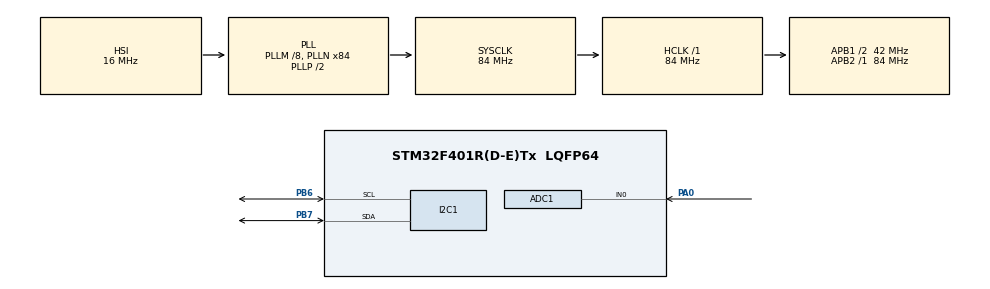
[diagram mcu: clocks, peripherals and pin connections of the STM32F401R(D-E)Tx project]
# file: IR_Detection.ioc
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ADC1.Channel-11\#ChannelRegularConversion=ADC_CHANNEL_0
<<<<<<< HEAD
ADC1.ClockPrescaler=ADC_CLOCK_SYNC_PCLK_DIV4
ADC1.ContinuousConvMode=DISABLE
ADC1.DMAContinuousRequests=ENABLE
ADC1.DataAlign=ADC_DATAALIGN_RIGHT
ADC1.DiscontinuousConvMode=ENABLE
ADC1.EOCSelection=ADC_EOC_SINGLE_CONV
ADC1.EnableAnalogWatchDog=false
ADC1.ExternalTrigConv=ADC_EXTERNALTRIGCONV_T2_TRGO
ADC1.ExternalTrigConvEdge=ADC_EXTERNALTRIGCONVEDGE_RISING
ADC1.InjNumberOfConversion=0
ADC1.NbrOfConversion=1
ADC1.NbrOfConversionFlag=1
ADC1.NbrOfDiscConversion=1
ADC1.Rank-11\#ChannelRegularConversion=1
ADC1.Resolution=ADC_RESOLUTION_12B
ADC1.SamplingTime-11\#ChannelRegularConversion=ADC_SAMPLETIME_480CYCLES
ADC1.ScanConvMode=DISABLE
ADC1.master=1
Dma.ADC1.0.Direction=DMA_PERIPH_TO_MEMORY
Dma.ADC1.0.FIFOMode=DMA_FIFOMODE_DISABLE
Dma.ADC1.0.Instance=DMA2_Stream0
Dma.ADC1.0.MemDataAlignment=DMA_MDATAALIGN_WORD
Dma.ADC1.0.MemInc=DMA_MINC_ENABLE
Dma.ADC1.0.Mode=DMA_CIRCULAR
Dma.ADC1.0.PeriphDataAlignment=DMA_PDATAALIGN_WORD
Dma.ADC1.0.PeriphInc=DMA_PINC_DISABLE
Dma.ADC1.0.Priority=DMA_PRIORITY_HIGH
Dma.Request0=ADC1
=======
ADC1.ContinuousConvMode=ENABLE
ADC1.EOCSelection=ADC_EOC_SEQ_CONV
ADC1.NbrOfConversionFlag=1
ADC1.Rank-11\#ChannelRegularConversion=1
ADC1.SamplingTime-11\#ChannelRegularConversion=ADC_SAMPLETIME_3CYCLES
ADC1.master=1
>>>>>>> 8014290a4e73a4bcc694909df24c79fa8737d68c
Mcu.Family=STM32F4
<<<<<<< HEAD
=======
>>>>>>> 8014290a4e73a4bcc694909df24c79fa8737d68c
Mcu.Name=STM32F401R(D-E)Tx
Mcu.Package=LQFP64
<<<<<<< HEAD
=======
>>>>>>> 8014290a4e73a4bcc694909df24c79fa8737d68c
<<<<<<< HEAD
NVIC.DMA2_Stream0_IRQn=true\:0\:0\:false\:false\:true\:false
=======
>>>>>>> 8014290a4e73a4bcc694909df24c79fa8737d68c
NVIC.PriorityGroup=NVIC_PRIORITYGROUP_4
PA0-WKUP.Signal=ADCx_IN0
PB6.Mode=I2C
PB6.Signal=I2C1_SCL
PB7.Mode=I2C
PB7.Signal=I2C1_SDA
ProjectManager.HeapSize=0x200
ProjectManager.StackSize=0x400
ProjectManager.TargetToolchain=Makefile
<<<<<<< HEAD
=======
>>>>>>> 8014290a4e73a4bcc694909df24c79fa8737d68c
RCC.48MHZClocksFreq_Value=42000000
RCC.AHBFreq_Value=84000000
RCC.APB1CLKDivider=RCC_HCLK_DIV2
RCC.APB1Freq_Value=42000000
RCC.APB1TimFreq_Value=84000000
RCC.APB2Freq_Value=84000000
RCC.APB2TimFreq_Value=84000000
RCC.CortexFreq_Value=84000000
RCC.HCLKFreq_Value=84000000
RCC.HSE_VALUE=25000000
RCC.HSI_VALUE=16000000
RCC.LSE_VALUE=32768
RCC.PLLM=8
RCC.PLLN=84
RCC.SYSCLKFreq_VALUE=84000000
RCC.SYSCLKSource=RCC_SYSCLKSOURCE_PLLCLK
RCC.VCOOutputFreq_Value=168000000
SH.ADCx_IN0.0=ADC1_IN0,IN0
<<<<<<< HEAD
TIM2.Channel-PWM\ Generation1\ No\ Output=TIM_CHANNEL_1
TIM2.OCFastMode_PWM-PWM\ Generation1\ No\ Output=TIM_OCFAST_DISABLE
TIM2.Period=20
TIM2.Prescaler=2
TIM2.TIM_MasterOutputTrigger=TIM_TRGO_OC1
TIM2.TIM_MasterSlaveMode=TIM_MASTERSLAVEMODE_ENABLE
VP_TIM2_VS_ClockSourceINT.Mode=Internal
VP_TIM2_VS_no_output1.Mode=PWM Generation1 No Output
=======
>>>>>>> 8014290a4e73a4bcc694909df24c79fa8737d68c
board=custom

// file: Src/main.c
/**
  ******************************************************************************
  * @file           : main.c
  * @brief          : Main program body
  ******************************************************************************
  ** This notice applies to any and all portions of this file
  * that are not between comment pairs USER CODE BEGIN and
  * USER CODE END. Other portions of this file, whether
  * inserted by the user or by software development tools
  * are owned by their respective copyright owners.
  *
  * COPYRIGHT(c) 2018 STMicroelectronics
  *
  * Redistribution and use in source and binary forms, with or without modification,
  * are permitted provided that the following conditions are met:
  *   1. Redistributions of source code must retain the above copyright notice,
  *      this list of conditions and the following disclaimer.
  *   2. Redistributions in binary form must reproduce the above copyright notice,
  *      this list of conditions and the following disclaimer in the documentation
  *      and/or other materials provided with the distribution.
  *   3. Neither the name of STMicroelectronics nor the names of its contributors
  *      may be used to endorse or promote products derived from this software
  *      without specific prior written permission.
  *
  * THIS SOFTWARE IS PROVIDED BY THE COPYRIGHT HOLDERS AND CONTRIBUTORS "AS IS"
  * AND ANY EXPRESS OR IMPLIED WARRANTIES, INCLUDING, BUT NOT LIMITED TO, THE
  * IMPLIED WARRANTIES OF MERCHANTABILITY AND FITNESS FOR A PARTICULAR PURPOSE ARE
  * DISCLAIMED. IN NO EVENT SHALL THE COPYRIGHT HOLDER OR CONTRIBUTORS BE LIABLE
  * FOR ANY DIRECT, INDIRECT, INCIDENTAL, SPECIAL, EXEMPLARY, OR CONSEQUENTIAL
  * DAMAGES (INCLUDING, BUT NOT LIMITED TO, PROCUREMENT OF SUBSTITUTE GOODS OR
  * SERVICES; LOSS OF USE, DATA, OR PROFITS; OR BUSINESS INTERRUPTION) HOWEVER
  * CAUSED AND ON ANY THEORY OF LIABILITY, WHETHER IN CONTRACT, STRICT LIABILITY,
  * OR TORT (INCLUDING NEGLIGENCE OR OTHERWISE) ARISING IN ANY WAY OUT OF THE USE
  * OF THIS SOFTWARE, EVEN IF ADVISED OF THE POSSIBILITY OF SUCH DAMAGE.
  *
  ******************************************************************************
  */
#include "main.h"
#include "stm32f4xx_hal.h"

/* USER CODE BEGIN Includes */
#include "filter.h"
#include "ssd1306.h"
#include "stdlib.h"
#include "math.h"

#define WINDOW_SIZE 1024
#define SAMPLING_RATE 42079
#define HIST_LENGTH 500
/* USER CODE END Includes */

ADC_HandleTypeDef hadc1;
DMA_HandleTypeDef hdma_adc1;

I2C_HandleTypeDef hi2c1;

TIM_HandleTypeDef htim2;

/* USER CODE BEGIN PV */
/* Private variables ---------------------------------------------------------*/

/* USER CODE END PV */

void SystemClock_Config(void);
static void MX_GPIO_Init(void);
static void MX_DMA_Init(void);
static void MX_ADC1_Init(void);
static void MX_I2C1_Init(void);
static void MX_TIM2_Init(void);

/* USER CODE BEGIN PFP */
/* Private function prototypes -----------------------------------------------*/

/* USER CODE END PFP */

/* USER CODE BEGIN 0 */
volatile uint8_t dealt_with = 0;
int value_adc[1024] = {0};

// char *adc = (char *)malloc(13 * sizeof(char));
int calc = 0;
double value;
double prev_val;
uint32_t n = 0;
uint16_t yes_no = 0;
double d1 = 0;
double d2 = 0;
double y = 0;
double total_power = 1;
double f_step, f_step_normalized, k, normalizedfreq, w_real;
// static circ_bufsum_t cbuf;
// circ_bufsum_t cbuf;

/* USER CODE END 0 */

int main(void)
{

  /* MCU Configuration----------------------------------------------------------*/

  /* Reset of all peripherals, Initializes the Flash interface and the Systick. */
  HAL_Init();

  /* Configure the system clock */
  SystemClock_Config();

  /* Initialize all configured peripherals */
  MX_GPIO_Init();
  MX_DMA_Init();
  MX_ADC1_Init();
  MX_I2C1_Init();
  MX_TIM2_Init();
  /* USER CODE BEGIN 2 */
  ssd1306_Init();
  HAL_TIM_Base_Start_IT(&htim2);
  HAL_ADC_Start_DMA(&hadc1, value_adc, 1024);

  ssd1306_Fill(Black);
  ssd1306_SetCursor(0, 0);
  ssd1306_WriteString("horray", Font_11x18, White);
  ssd1306_UpdateScreen();
  HAL_Delay(3000);

  f_step = SAMPLING_RATE / (double)WINDOW_SIZE;
  f_step_normalized = 1.0 / WINDOW_SIZE;
  k = 1000 / f_step;
  normalizedfreq = k * f_step_normalized;
  w_real = 2.0 * cos(2.0 * PI * normalizedfreq);
  /* USER CODE END 2 */

  /* Infinite loop */
  /* USER CODE BEGIN WHILE */
  while (1)
  {
    if (calc)
    {
      value = goertzel(value_adc, SAMPLING_RATE, 1000, WINDOW_SIZE);
      char *adc = (char *)malloc(13 * sizeof(char));
      ssd1306_Fill(Black);
      ssd1306_SetCursor(0, 0);
      sprintf(adc, "n: %d", (int)n);
      ssd1306_WriteString(adc, Font_11x18, White);
      ssd1306_SetCursor(0, 18);
      sprintf(adc, "%d", (int)value_adc[0]);
      ssd1306_WriteString(adc, Font_11x18, White);

      int pre_decimal = (int)(value / 1);
      int post_decimal = (int)((value - (double)pre_decimal) * 100);

      sprintf(adc, "?: %d %d.%d", yes_no, pre_decimal, post_decimal);
      ssd1306_SetCursor(0, 36);
      ssd1306_WriteString(adc, Font_11x18, White);
      ssd1306_UpdateScreen();
      HAL_Delay(1000);
    }

  /* USER CODE END WHILE */

  }

}

void SystemClock_Config(void)
{

  RCC_OscInitTypeDef RCC_OscInitStruct;
  RCC_ClkInitTypeDef RCC_ClkInitStruct;

    /**Configure the main internal regulator output voltage
    */
  __HAL_RCC_PWR_CLK_ENABLE();

  __HAL_PWR_VOLTAGESCALING_CONFIG(PWR_REGULATOR_VOLTAGE_SCALE2);

    /**Initializes the CPU, AHB and APB busses clocks
    */
  RCC_OscInitStruct.OscillatorType = RCC_OSCILLATORTYPE_HSI;
  RCC_OscInitStruct.HSIState = RCC_HSI_ON;
  RCC_OscInitStruct.HSICalibrationValue = 16;
  RCC_OscInitStruct.PLL.PLLState = RCC_PLL_ON;
  RCC_OscInitStruct.PLL.PLLSource = RCC_PLLSOURCE_HSI;
  RCC_OscInitStruct.PLL.PLLM = 8;
  RCC_OscInitStruct.PLL.PLLN = 84;
  RCC_OscInitStruct.PLL.PLLP = RCC_PLLP_DIV2;
  RCC_OscInitStruct.PLL.PLLQ = 4;
  if (HAL_RCC_OscConfig(&RCC_OscInitStruct) != HAL_OK)
  {
    _Error_Handler(__FILE__, __LINE__);
  }

    /**Initializes the CPU, AHB and APB busses clocks
    */
  RCC_ClkInitStruct.ClockType = RCC_CLOCKTYPE_HCLK|RCC_CLOCKTYPE_SYSCLK
                              |RCC_CLOCKTYPE_PCLK1|RCC_CLOCKTYPE_PCLK2;
  RCC_ClkInitStruct.SYSCLKSource = RCC_SYSCLKSOURCE_PLLCLK;
  RCC_ClkInitStruct.AHBCLKDivider = RCC_SYSCLK_DIV1;
  RCC_ClkInitStruct.APB1CLKDivider = RCC_HCLK_DIV2;
  RCC_ClkInitStruct.APB2CLKDivider = RCC_HCLK_DIV1;

  if (HAL_RCC_ClockConfig(&RCC_ClkInitStruct, FLASH_LATENCY_2) != HAL_OK)
  {
    _Error_Handler(__FILE__, __LINE__);
  }

    /**Configure the Systick interrupt time
    */
  HAL_SYSTICK_Config(HAL_RCC_GetHCLKFreq()/1000);

    /**Configure the Systick
    */
  HAL_SYSTICK_CLKSourceConfig(SYSTICK_CLKSOURCE_HCLK);

  /* SysTick_IRQn interrupt configuration */
  HAL_NVIC_SetPriority(SysTick_IRQn, 0, 0);
}

/* ADC1 init function */
static void MX_ADC1_Init(void)
{

  ADC_ChannelConfTypeDef sConfig;

    /**Configure the global features of the ADC (Clock, Resolution, Data Alignment and number of conversion)
    */
  hadc1.Instance = ADC1;
  hadc1.Init.ClockPrescaler = ADC_CLOCK_SYNC_PCLK_DIV4;
  hadc1.Init.Resolution = ADC_RESOLUTION_12B;
  hadc1.Init.ScanConvMode = DISABLE;
  hadc1.Init.ContinuousConvMode = DISABLE;
  hadc1.Init.DiscontinuousConvMode = ENABLE;
  hadc1.Init.NbrOfDiscConversion = 1;
  hadc1.Init.ExternalTrigConvEdge = ADC_EXTERNALTRIGCONVEDGE_RISING;
  hadc1.Init.ExternalTrigConv = ADC_EXTERNALTRIGCONV_T2_TRGO;
  hadc1.Init.DataAlign = ADC_DATAALIGN_RIGHT;
  hadc1.Init.NbrOfConversion = 1;
  hadc1.Init.DMAContinuousRequests = ENABLE;
  hadc1.Init.EOCSelection = ADC_EOC_SINGLE_CONV;
  if (HAL_ADC_Init(&hadc1) != HAL_OK)
  {
    _Error_Handler(__FILE__, __LINE__);
  }

    /**Configure for the selected ADC regular channel its corresponding rank in the sequencer and its sample time.
    */
  sConfig.Channel = ADC_CHANNEL_0;
  sConfig.Rank = 1;
  sConfig.SamplingTime = ADC_SAMPLETIME_480CYCLES;
  if (HAL_ADC_ConfigChannel(&hadc1, &sConfig) != HAL_OK)
  {
    _Error_Handler(__FILE__, __LINE__);
  }

}

/* I2C1 init function */
static void MX_I2C1_Init(void)
{

  hi2c1.Instance = I2C1;
  hi2c1.Init.ClockSpeed = 100000;
  hi2c1.Init.DutyCycle = I2C_DUTYCYCLE_2;
  hi2c1.Init.OwnAddress1 = 0;
  hi2c1.Init.AddressingMode = I2C_ADDRESSINGMODE_7BIT;
  hi2c1.Init.DualAddressMode = I2C_DUALADDRESS_DISABLE;
  hi2c1.Init.OwnAddress2 = 0;
  hi2c1.Init.GeneralCallMode = I2C_GENERALCALL_DISABLE;
  hi2c1.Init.NoStretchMode = I2C_NOSTRETCH_DISABLE;
  if (HAL_I2C_Init(&hi2c1) != HAL_OK)
  {
    _Error_Handler(__FILE__, __LINE__);
  }

}

/* TIM2 init function */
static void MX_TIM2_Init(void)
{

  TIM_ClockConfigTypeDef sClockSourceConfig;
  TIM_MasterConfigTypeDef sMasterConfig;
  TIM_OC_InitTypeDef sConfigOC;

  htim2.Instance = TIM2;
  htim2.Init.Prescaler = 2;
  htim2.Init.CounterMode = TIM_COUNTERMODE_UP;
  htim2.Init.Period = 20;
  htim2.Init.ClockDivision = TIM_CLOCKDIVISION_DIV1;
  if (HAL_TIM_Base_Init(&htim2) != HAL_OK)
  {
    _Error_Handler(__FILE__, __LINE__);
  }

  sClockSourceConfig.ClockSource = TIM_CLOCKSOURCE_INTERNAL;
  if (HAL_TIM_ConfigClockSource(&htim2, &sClockSourceConfig) != HAL_OK)
  {
    _Error_Handler(__FILE__, __LINE__);
  }

  if (HAL_TIM_PWM_Init(&htim2) != HAL_OK)
  {
    _Error_Handler(__FILE__, __LINE__);
  }

  sMasterConfig.MasterOutputTrigger = TIM_TRGO_OC1;
  sMasterConfig.MasterSlaveMode = TIM_MASTERSLAVEMODE_ENABLE;
  if (HAL_TIMEx_MasterConfigSynchronization(&htim2, &sMasterConfig) != HAL_OK)
  {
    _Error_Handler(__FILE__, __LINE__);
  }

  sConfigOC.OCMode = TIM_OCMODE_PWM1;
  sConfigOC.Pulse = 0;
  sConfigOC.OCPolarity = TIM_OCPOLARITY_HIGH;
  sConfigOC.OCFastMode = TIM_OCFAST_DISABLE;
  if (HAL_TIM_PWM_ConfigChannel(&htim2, &sConfigOC, TIM_CHANNEL_1) != HAL_OK)
  {
    _Error_Handler(__FILE__, __LINE__);
  }

}

static void MX_DMA_Init(void)
{
  /* DMA controller clock enable */
  __HAL_RCC_DMA2_CLK_ENABLE();

  /* DMA interrupt init */
  /* DMA2_Stream0_IRQn interrupt configuration */
  HAL_NVIC_SetPriority(DMA2_Stream0_IRQn, 0, 0);
  HAL_NVIC_EnableIRQ(DMA2_Stream0_IRQn);

}

/** Pinout Configuration
*/
static void MX_GPIO_Init(void)
{

  /* GPIO Ports Clock Enable */
  __HAL_RCC_GPIOA_CLK_ENABLE();
  __HAL_RCC_GPIOB_CLK_ENABLE();

}

/* USER CODE BEGIN 4 */
void HAL_ADC_ConvCpltCallback(ADC_HandleTypeDef *hadc)
{
//   ++n;
//   // value = circular_goertzel_stream((double)value_adc[0] - 2048, 1000, SAMPLING_RATE, WINDOW_SIZE);
//   total_power += ((double)value_adc[0] - 2048) * ((double)value_adc[0] - 2048);
//   y = ((double)value_adc[0] - 2048) + w_real * d1 - d2 - 100;
//   d2 = d1;
//   d1 = y;
//   value = (d2 * d2 + d1 * d1 - w_real * d1 * d2) / total_power;

//   if (n % HIST_LENGTH == 0)
//   {
//     yes_no = (value - prev_val) > 0 ? 1 : 0;
//     prev_val = value;
//   }
  calc = 1;
}
/* USER CODE END 4 */

void _Error_Handler(char *file, int line)
{
  while (1)
  {
  }
}

/************************ (C) COPYRIGHT STMicroelectronics *****END OF FILE****/
